# STM32G0B0xx register map
File version: 1.0
Registers are 32-bit, read-write, reset 0x0 unless marked. A register's access mark holds for its fields unless they carry their own. Offsets are from the block's base; [hi:lo] are bit positions; {n}, {i} and the like mark numbered series; 'fields as' and 'values as' point back to an identical list.

## USB_DRD_PMA_BUFF — Universal Serial Bus PacketMemoryArea Buffer Descriptor Table
Base 0x40009800
0x00 TXBD — Transmission buffer address
0x04 RXBD — Reception buffer address

## TAMP — Tamper and backup registers
Base 0x4000B000
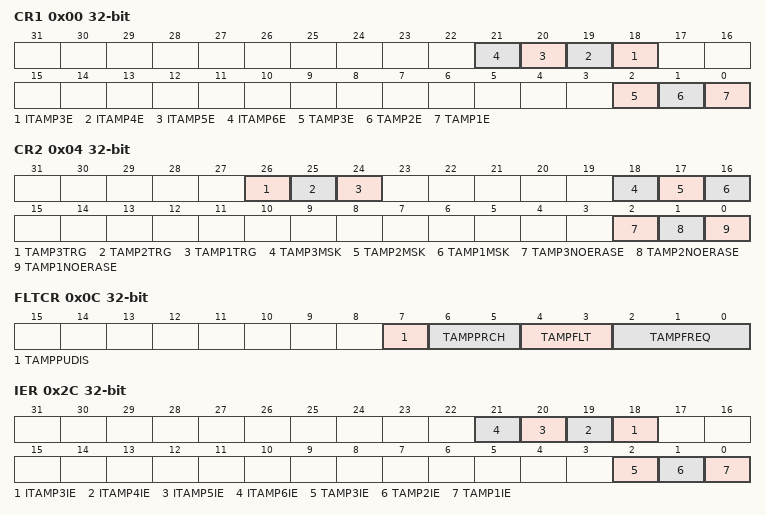
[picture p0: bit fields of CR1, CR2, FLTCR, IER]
0x00 CR1 — TAMP configuration register 1
  [n+15] ITAMP{n}E (n=3..6), [2] TAMP3E, [1] TAMP2E, [0] TAMP1E
0x04 CR2 — TAMP configuration register 2
  [26] TAMP3TRG, [25] TAMP2TRG, [24] TAMP1TRG, [18] TAMP3MSK, [17] TAMP2MSK, [16] TAMP1MSK, [2] TAMP3NOERASE, [1] TAMP2NOERASE, [0] TAMP1NOERASE
0x0C FLTCR — Reserved
  [7] TAMPPUDIS
  [6:5] TAMPPRCH
    0=DURATION_1RTCCLK (Tamper pins are pre-charged before sampling during 1 RTCCLK cycle); 1=DURATION_2RTCCLK (Tamper pins are pre-charged before sampling during 2 RTCCLK cycles); 2=DURATION_4RTCCLK (Tamper pins are pre-charged before sampling during 4 RTCCLK cycles); 3=DURATION_8RTCCLK (Tamper pins are pre-charged before sampling during 8 RTCCLK cycles)
  [4:3] TAMPFLT
    0=DISABLE (Tamper filter is disabled); 1=FILTER_2SAMPLE (Tamper is activated after 2 consecutive samples at the active level); 2=FILTER_4SAMPLE (Tamper is activated after 4 consecutive samples at the active level); 3=FILTER_8SAMPLE (Tamper is activated after 8 consecutive samples at the active level.)
  [2:0] TAMPFREQ
    0=SAMPLFREQDIV_32768 (Each of the tamper inputs are sampled with a frequency = RTCCLK / 32768); 1=SAMPLFREQDIV_16384 (Each of the tamper inputs are sampled with a frequency = RTCCLK / 16384); 2=SAMPLFREQDIV_8192 (Each of the tamper inputs are sampled with a frequency = RTCCLK / 8192); 3=SAMPLFREQDIV_4096 (Each of the tamper inputs are sampled with a frequency = RTCCLK / 4096); 4=SAMPLFREQDIV_2048 (Each of the tamper inputs are sampled with a frequency = RTCCLK / 2048); 5=SAMPLFREQDIV_1024 (Each of the tamper inputs are sampled with a frequency = RTCCLK / 1024); 6=SAMPLFREQDIV_512 (Each of the tamper inputs are sampled with a frequency = RTCCLK / 512); 7=SAMPLFREQDIV_256 (Each of the tamper inputs are sampled with a frequency = RTCCLK / 256)
0x2C IER — TAMP Interrupt enable register
  [n+15] ITAMP{n}IE (n=3..6), [2] TAMP3IE, [1] TAMP2IE, [0] TAMP1IE
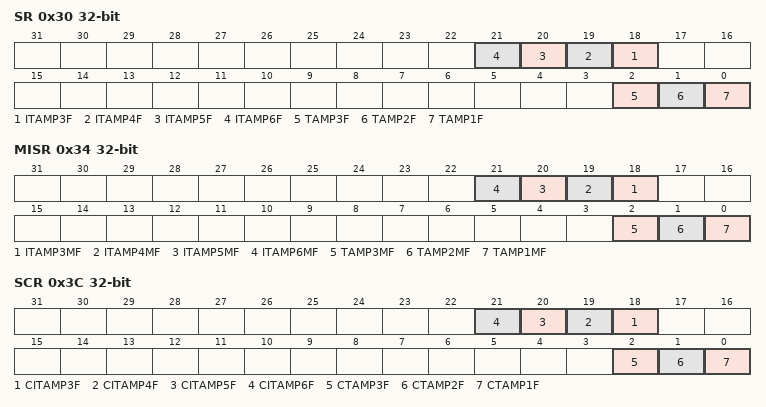
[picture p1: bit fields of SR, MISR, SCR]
0x30 SR — TAMP Status register
  [n+15] ITAMP{n}F (n=3..6), [2] TAMP3F, [1] TAMP2F, [0] TAMP1F
0x34 MISR — TAMP Masked Interrupt Status register
  [n+15] ITAMP{n}MF (n=3..6), [2] TAMP3MF, [1] TAMP2MF, [0] TAMP1MF
0x3C SCR — TAMP Status clear register
  [n+15] CITAMP{n}F (n=3..6), [2] CTAMP3F, [1] CTAMP2F, [0] CTAMP1F
{0x100+4i} BKP{i}R (i=0..4) — TAMP backup register {i}

## DBG — Debug MCU
Base 0x40015800
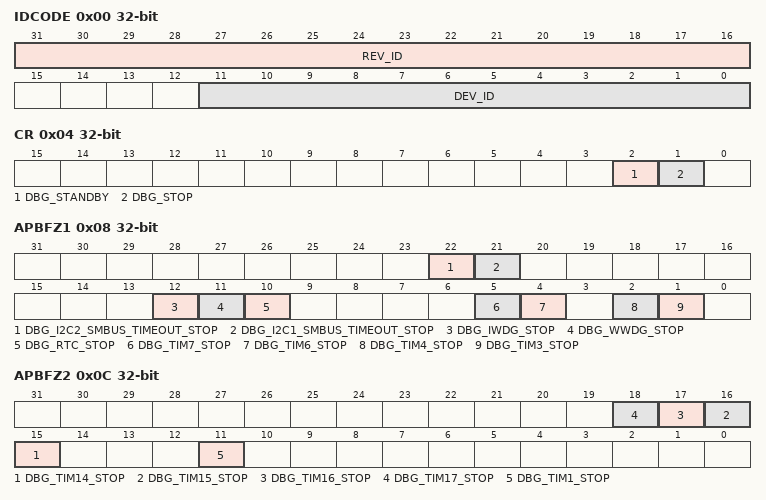
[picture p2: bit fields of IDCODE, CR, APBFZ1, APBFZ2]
0x00 IDCODE — MCU device ID code
  [31:16] REV_ID, [11:0] DEV_ID
0x04 CR — Debug configuration register
  [2] DBG_STANDBY, [1] DBG_STOP
0x08 APBFZ1 — Debug APB freeze register 1
  [22] DBG_I2C2_SMBUS_TIMEOUT_STOP, [21] DBG_I2C1_SMBUS_TIMEOUT_STOP, [12] DBG_IWDG_STOP, [11] DBG_WWDG_STOP, [10] DBG_RTC_STOP, [5] DBG_TIM7_STOP, [4] DBG_TIM6_STOP, [2] DBG_TIM4_STOP, [1] DBG_TIM3_STOP
0x0C APBFZ2 — Debug APB freeze register 2
  [n+1] DBG_TIM{n}_STOP (n=14..17), [11] DBG_TIM1_STOP

## DMA1
Base 0x40020000
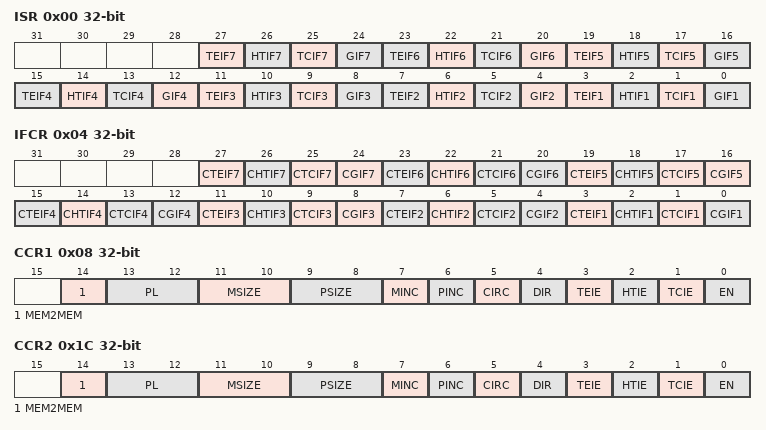
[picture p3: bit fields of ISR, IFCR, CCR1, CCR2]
0x00 ISR — DMA interrupt status register
  [4n-1] TEIF{n} (n=1..7) — Channel {n} Transfer Error flag
  [4n-2] HTIF{n} (n=1..7) — Channel {n} Half Transfer flag
  [4n-3] TCIF{n} (n=1..7) — Channel {n} Transfer Complete flag
  [4n-4] GIF{n} (n=1..7) — Channel {n} Global interrupt flag
0x04 IFCR — DMA interrupt flag clear register
  [4n-1] CTEIF{n} (n=1..7) — Channel {n} Transfer Error clear
  [4n-2] CHTIF{n} (n=1..7) — Channel {n} Half Transfer clear
  [4n-3] CTCIF{n} (n=1..7) — Channel {n} Transfer Complete clear
  [4n-4] CGIF{n} (n=2..7) — Channel {n} Global interrupt clear
  [0] CGIF1 — Channel 1 Global interrupt clearr
0x08 CCR1 — DMA channel x configuration register
  [14] MEM2MEM — Memory to memory mode
  [13:12] PL — PL[1:0] bits(Channel Priority level)
  [11:10] MSIZE — MSIZE[1:0] bits (Memory size)
  [9:8] PSIZE — PSIZE[1:0] bits (Peripheral size)
  [7] MINC — Memory increment mode
  [6] PINC — Peripheral increment mode
  [5] CIRC — Circular mode
  [4] DIR — Data transfer direction
  [3] TEIE — Transfer error interrupt enable
  [2] HTIE — Half Transfer interrupt enable
  [1] TCIE — Transfer complete interrupt enable
  [0] EN — Channel enable
0x0C CNDTR1 — DMA channel x number of data register
  [15:0] NDT — Number of data to Transfer
0x10 CPAR1 — DMA channel x peripheral address register
  [31:0] PA — Peripheral Address
{0x0+0x14*i} CMAR{i} (i=1..7) — DMA channel x memory address register
  [31:0] MA — Memory Address
0x1C CCR2 — DMA channel x configuration register
  fields as CCR1
0x20 CNDTR2 — DMA channel x number of data register
  [15:0] NDT — Number of data to Transfer
0x24 CPAR2 — DMA channel x peripheral address register
  [31:0] PA — Peripheral Address
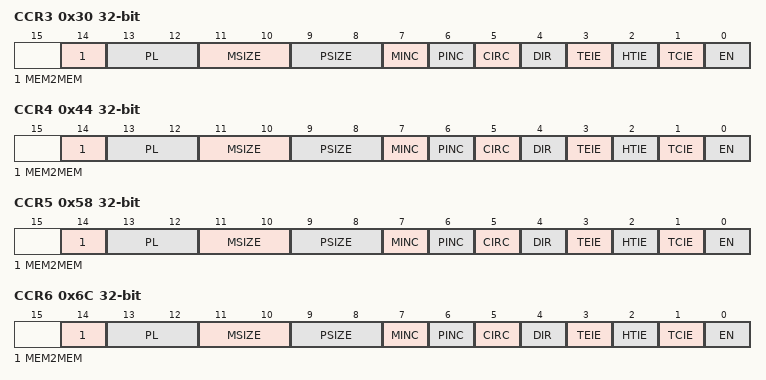
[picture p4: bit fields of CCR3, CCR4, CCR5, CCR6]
0x30 CCR3 — DMA channel x configuration register
  fields as CCR1
0x34 CNDTR3 — DMA channel x number of data register
  [15:0] NDT — Number of data to Transfer
0x38 CPAR3 — DMA channel x peripheral address register
  [31:0] PA — Peripheral Address
0x44 CCR4 — DMA channel x configuration register
  fields as CCR1
0x48 CNDTR4 — DMA channel x number of data register
  [15:0] NDT — Number of data to Transfer
0x4C CPAR4 — DMA channel x peripheral address register
  [31:0] PA — Peripheral Address
0x58 CCR5 — DMA channel x configuration register
  fields as CCR1
0x5C CNDTR5 — DMA channel x number of data register
  [15:0] NDT — Number of data to Transfer
0x60 CPAR5 — DMA channel x peripheral address register
  [31:0] PA — Peripheral Address
0x6C CCR6 — DMA channel x configuration register
  fields as CCR1
0x70 CNDTR6 — DMA channel x number of data register
  [15:0] NDT — Number of data to Transfer
0x74 CPAR6 — DMA channel x peripheral address register
  [31:0] PA — Peripheral Address
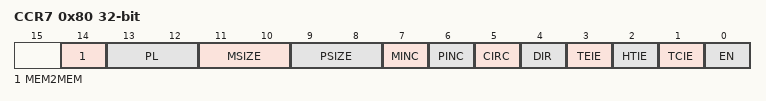
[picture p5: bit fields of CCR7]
0x80 CCR7 — DMA channel x configuration register
  fields as CCR1
0x84 CNDTR7 — DMA channel x number of data register
  [15:0] NDT — Number of data to Transfer
0x88 CPAR7 — DMA channel x peripheral address register
  [31:0] PA — Peripheral Address

## DMA2
Base 0x40020400
Registers as DMA1, without CCR6, CNDTR6, CPAR6, CMAR6, CCR7, CNDTR7, CPAR7, CMAR7.
